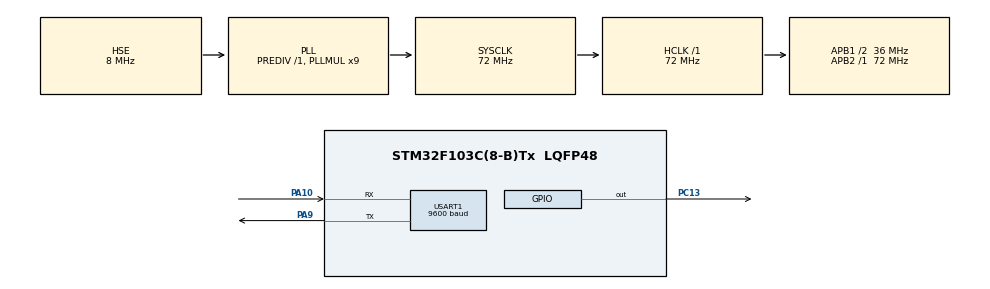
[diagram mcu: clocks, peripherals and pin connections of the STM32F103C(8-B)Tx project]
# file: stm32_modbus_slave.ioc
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Mcu.Family=STM32F1
Mcu.Name=STM32F103C(8-B)Tx
Mcu.Package=LQFP48
NVIC.PriorityGroup=NVIC_PRIORITYGROUP_4
NVIC.USART1_IRQn=true\:0\:0\:false\:false\:true\:true\:true\:true
PA10.Mode=Asynchronous
PA10.Signal=USART1_RX
PA9.Mode=Asynchronous
PA9.Signal=USART1_TX
PC13-TAMPER-RTC.Signal=GPIO_Output
PD0-OSC_IN.Mode=HSE-External-Oscillator
PD0-OSC_IN.Signal=RCC_OSC_IN
PD1-OSC_OUT.Mode=HSE-External-Oscillator
PD1-OSC_OUT.Signal=RCC_OSC_OUT
ProjectManager.HeapSize=0x200
ProjectManager.StackSize=0x400
ProjectManager.TargetToolchain=STM32CubeIDE
RCC.AHBFreq_Value=72000000
RCC.APB1CLKDivider=RCC_HCLK_DIV2
RCC.APB1Freq_Value=36000000
RCC.APB1TimFreq_Value=72000000
RCC.APB2Freq_Value=72000000
RCC.APB2TimFreq_Value=72000000
RCC.HCLKFreq_Value=72000000
RCC.PLLMUL=RCC_PLL_MUL9
RCC.PLLSourceVirtual=RCC_PLLSOURCE_HSE
RCC.SYSCLKFreq_VALUE=72000000
RCC.SYSCLKSource=RCC_SYSCLKSOURCE_PLLCLK
RCC.USBFreq_Value=72000000
USART1.BaudRate=9600
USART1.VirtualMode=VM_ASYNC
VP_SYS_VS_ND.Mode=No_Debug
board=custom

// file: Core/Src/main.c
/* USER CODE BEGIN Header */
/**
  ******************************************************************************
  * @file           : main.c
  * @brief          : Main program body
  ******************************************************************************
  * @attention
  *
  * Copyright (c) 2026 STMicroelectronics.
  * All rights reserved.
  *
  * This software is licensed under terms that can be found in the LICENSE file
  * in the root directory of this software component.
  * If no LICENSE file comes with this software, it is provided AS-IS.
  *
  ******************************************************************************
  */
/* USER CODE END Header */
#include "main.h"

UART_HandleTypeDef huart1;

/* USER CODE BEGIN PV */
uint8_t rx_data;
uint8_t rx_buffer[8];
uint8_t rx_index = 0;
/* USER CODE END PV */

void SystemClock_Config(void);
static void MX_GPIO_Init(void);
static void MX_USART1_UART_Init(void);

int main(void)
{

  /* MCU Configuration--------------------------------------------------------*/

  /* Reset of all peripherals, Initializes the Flash interface and the Systick. */
  HAL_Init();

  /* Configure the system clock */
  SystemClock_Config();

  /* Initialize all configured peripherals */
  MX_GPIO_Init();
  MX_USART1_UART_Init();
  HAL_UART_Receive_IT(&huart1, &rx_data, 1); // Start UART reception in interrupt mode

  /* Infinite loop */
  while (1)
  {

  }
}

void SystemClock_Config(void)
{
  RCC_OscInitTypeDef RCC_OscInitStruct = {0};
  RCC_ClkInitTypeDef RCC_ClkInitStruct = {0};

  /** Initializes the RCC Oscillators according to the specified parameters
  * in the RCC_OscInitTypeDef structure.
  */
  RCC_OscInitStruct.OscillatorType = RCC_OSCILLATORTYPE_HSE;
  RCC_OscInitStruct.HSEState = RCC_HSE_ON;
  RCC_OscInitStruct.HSEPredivValue = RCC_HSE_PREDIV_DIV1;
  RCC_OscInitStruct.HSIState = RCC_HSI_ON;
  RCC_OscInitStruct.PLL.PLLState = RCC_PLL_ON;
  RCC_OscInitStruct.PLL.PLLSource = RCC_PLLSOURCE_HSE;
  RCC_OscInitStruct.PLL.PLLMUL = RCC_PLL_MUL9;
  if (HAL_RCC_OscConfig(&RCC_OscInitStruct) != HAL_OK)
  {
    Error_Handler();
  }

  /** Initializes the CPU, AHB and APB buses clocks
  */
  RCC_ClkInitStruct.ClockType = RCC_CLOCKTYPE_HCLK|RCC_CLOCKTYPE_SYSCLK
                              |RCC_CLOCKTYPE_PCLK1|RCC_CLOCKTYPE_PCLK2;
  RCC_ClkInitStruct.SYSCLKSource = RCC_SYSCLKSOURCE_PLLCLK;
  RCC_ClkInitStruct.AHBCLKDivider = RCC_SYSCLK_DIV1;
  RCC_ClkInitStruct.APB1CLKDivider = RCC_HCLK_DIV2;
  RCC_ClkInitStruct.APB2CLKDivider = RCC_HCLK_DIV1;

  if (HAL_RCC_ClockConfig(&RCC_ClkInitStruct, FLASH_LATENCY_2) != HAL_OK)
  {
    Error_Handler();
  }
}

static void MX_USART1_UART_Init(void)
{

  huart1.Instance = USART1;
  huart1.Init.BaudRate = 9600;
  huart1.Init.WordLength = UART_WORDLENGTH_8B;
  huart1.Init.StopBits = UART_STOPBITS_1;
  huart1.Init.Parity = UART_PARITY_NONE;
  huart1.Init.Mode = UART_MODE_TX_RX;
  huart1.Init.HwFlowCtl = UART_HWCONTROL_NONE;
  huart1.Init.OverSampling = UART_OVERSAMPLING_16;
  if (HAL_UART_Init(&huart1) != HAL_OK)
  {
    Error_Handler();
  }

}

static void MX_GPIO_Init(void)
{
  GPIO_InitTypeDef GPIO_InitStruct = {0};

  /* GPIO Ports Clock Enable */
  __HAL_RCC_GPIOC_CLK_ENABLE();
  __HAL_RCC_GPIOD_CLK_ENABLE();
  __HAL_RCC_GPIOA_CLK_ENABLE();

  /*Configure GPIO pin Output Level */
  HAL_GPIO_WritePin(GPIOC, GPIO_PIN_13, GPIO_PIN_RESET);

  /*Configure GPIO pin : PC13 */
  GPIO_InitStruct.Pin = GPIO_PIN_13;
  GPIO_InitStruct.Mode = GPIO_MODE_OUTPUT_PP;
  GPIO_InitStruct.Pull = GPIO_NOPULL;
  GPIO_InitStruct.Speed = GPIO_SPEED_FREQ_LOW;
  HAL_GPIO_Init(GPIOC, &GPIO_InitStruct);

}

/* USER CODE BEGIN 4 */
uint16_t Modbus_CRC16(uint8_t *data, uint16_t length) {
    uint16_t crc = 0xFFFF;
    for (uint16_t pos = 0; pos < length; pos++) {
        crc ^= (uint16_t)data[pos]; // XOR byte into least sig. byte of crc
        for (int i = 8; i != 0; i--) { // Loop over each bit
            if ((crc & 0x0001) != 0) { // If the LSB is set
                crc >>= 1; // Shift right
                crc ^= 0xA001; // XOR with polynomial
            } else {
                crc >>= 1; // Just shift right
            }
        }
    }
    return crc;
}

void HAL_UART_RxCpltCallback(UART_HandleTypeDef *huart) {
    if (huart->Instance == USART1) {
      if (rx_index == 0 && rx_data != 0x01) {
        HAL_UART_Receive_IT(&huart1, &rx_data, 1); // Restart UART reception in interrupt mode
        return; // Wait for the first byte to be the expected slave ID (0x01
      }
      rx_buffer[rx_index++] = rx_data; // Store received byte in buffer
      if (rx_index >= sizeof(rx_buffer)) {
        if (rx_buffer[0] == 0x01 && rx_buffer[1] == 0x05) { // Check for Modbus Write Coil command
            uint16_t calc_crc = Modbus_CRC16(rx_buffer, 6); // Calculate CRC for first 6 bytes
            uint16_t received_crc = rx_buffer[6] | (rx_buffer[7] << 8); // Extract received CRC

            if (calc_crc == received_crc) {
                // Valid Modbus command received, process it
                uint8_t slave_id = rx_buffer[0];
                uint16_t coil_address = (rx_buffer[2] << 8) | rx_buffer[3];
                uint8_t coil_value = rx_buffer[4] == 0xFF ? 1 : 0; // ON if 0xFF, OFF if 0x00

                // Here you can add code to handle the coil value (e.g., toggle an LED)
                if (coil_value) {
                    HAL_GPIO_WritePin(GPIOC, GPIO_PIN_13, GPIO_PIN_RESET); // Turn ON LED
                } else {
                    HAL_GPIO_WritePin(GPIOC, GPIO_PIN_13, GPIO_PIN_SET); // Turn OFF LED
                }
            }
            HAL_UART_Transmit(&huart1, rx_buffer, sizeof(rx_buffer), HAL_MAX_DELAY); // Echo back received frame
        }
        rx_index = 0; // Reset index if buffer is full
      }
    }
    HAL_UART_Receive_IT(&huart1, &rx_data, 1); // Restart UART reception in interrupt mode
}
/* USER CODE END 4 */

void Error_Handler(void)
{
  __disable_irq();
  while (1)
  {
  }
}
